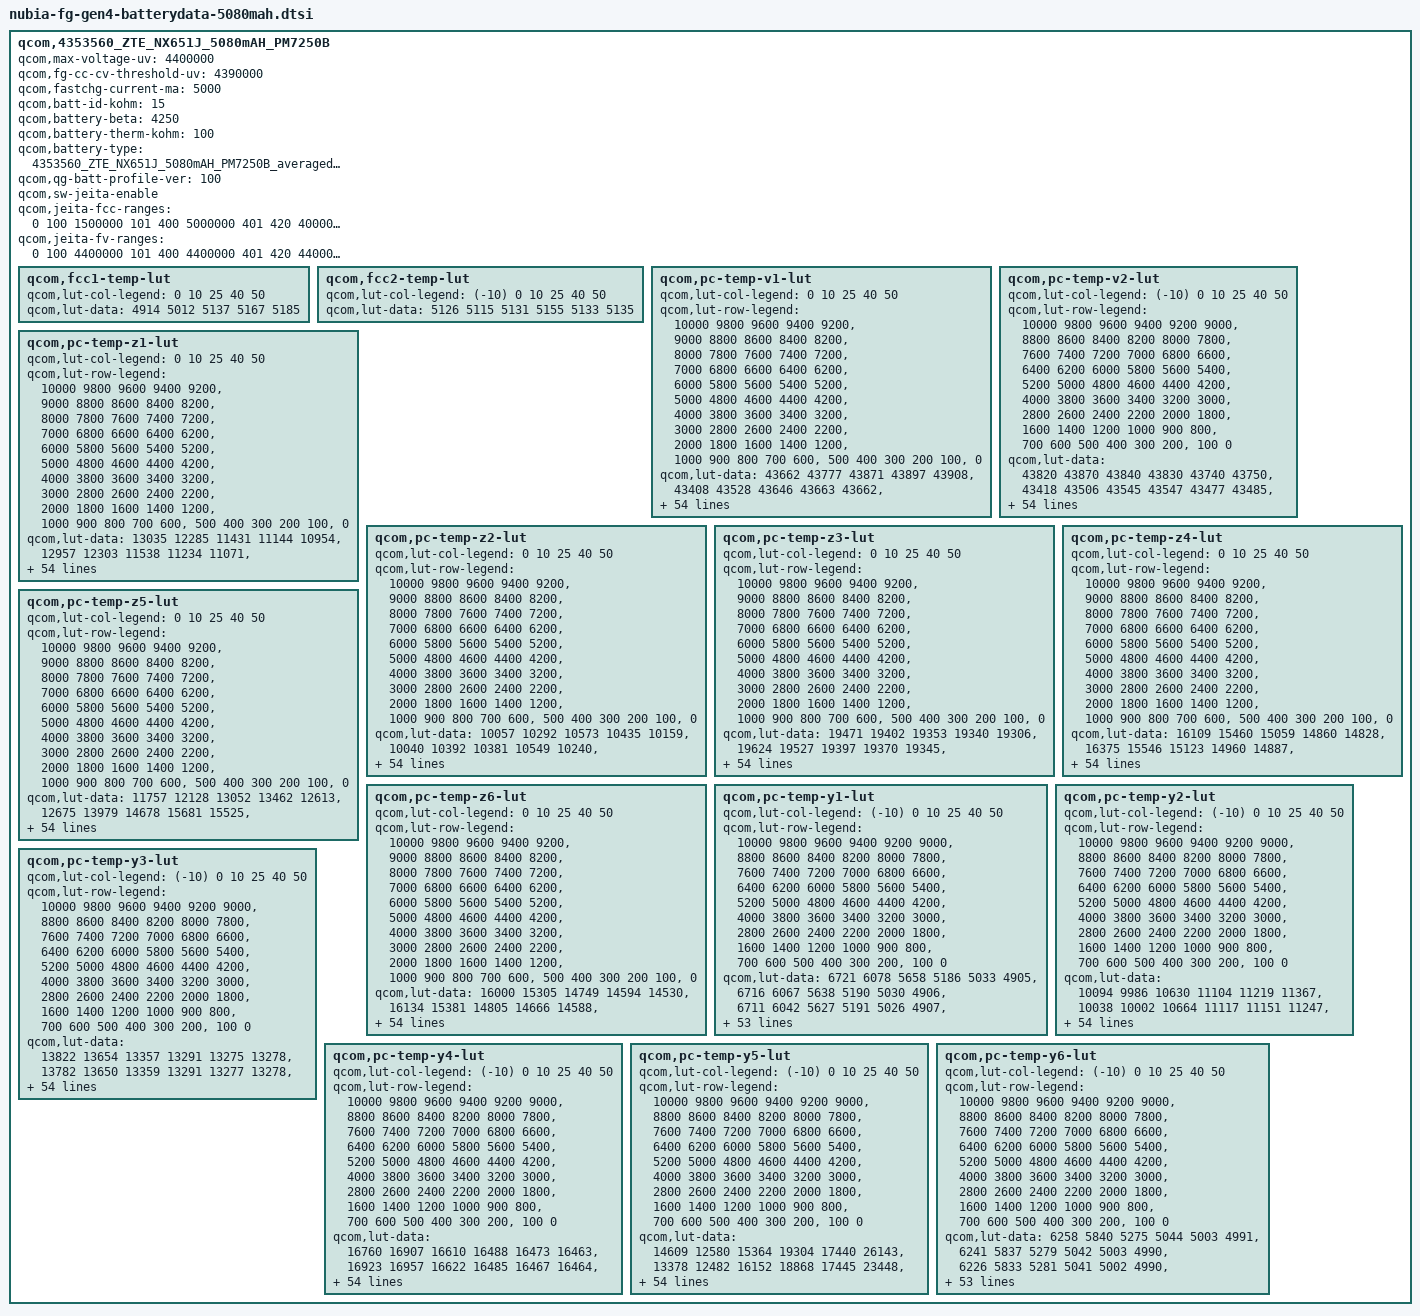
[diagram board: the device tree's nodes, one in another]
qcom,4353560_ZTE_NX651J_5080mAH_PM7250B {
    /* 4353560_ZTE_NX651J_5080mAH_PM7250B_averaged_MasterSlave_Dec16th2019 */
    qcom,max-voltage-uv = <4400000>;
    qcom,fg-cc-cv-threshold-uv = <4390000>;
    qcom,fastchg-current-ma = <5000>;
    qcom,batt-id-kohm = <15>;
    qcom,battery-beta = <4250>;
    qcom,battery-therm-kohm = <100>;
    qcom,battery-type = "4353560_ZTE_NX651J_5080mAH_PM7250B_averaged_MasterSlave_Dec16th2019";
    qcom,qg-batt-profile-ver = <100>;
	
	qcom,sw-jeita-enable;
	qcom,jeita-fcc-ranges = <0  100  1500000
							101 400  5000000
							401 420  4000000
							421 440  3500000
							441 520  1000000>;
	qcom,jeita-fv-ranges = <0   100  4400000
							101 400  4400000
							401 420  4400000
							421 440  4400000
							441 520  4100000>;
							
	qcom,fcc1-temp-lut {
		qcom,lut-col-legend = <0 10 25 40 50>;
		qcom,lut-data = <4914 5012 5137 5167 5185>;
	};

	qcom,fcc2-temp-lut {
		qcom,lut-col-legend = <(-10) 0 10 25 40 50>;
		qcom,lut-data = <5126 5115 5131 5155 5133 5135>;
	};

	qcom,pc-temp-v1-lut {
		qcom,lut-col-legend = <0 10 25 40 50>;
		qcom,lut-row-legend = <10000 9800 9600 9400 9200>,
			<9000 8800 8600 8400 8200>,
			<8000 7800 7600 7400 7200>,
			<7000 6800 6600 6400 6200>,
			<6000 5800 5600 5400 5200>,
			<5000 4800 4600 4400 4200>,
			<4000 3800 3600 3400 3200>,
			<3000 2800 2600 2400 2200>,
			<2000 1800 1600 1400 1200>,
			<1000 900 800 700 600>,
			<500 400 300 200 100>,
			<0>;
		qcom,lut-data = <43662 43777 43871 43897 43908>,
			<43408 43528 43646 43663 43662>,
			<43151 43282 43401 43429 43431>,
			<42897 43039 43155 43192 43200>,
			<42656 42799 42914 42959 42970>,
			<42425 42563 42674 42725 42740>,
			<42202 42332 42438 42491 42508>,
			<41988 42106 42205 42256 42274>,
			<41782 41885 41977 42024 42041>,
			<41580 41669 41751 41795 41812>,
			<41382 41466 41530 41570 41585>,
			<41185 41274 41321 41350 41364>,
			<40988 41078 41122 41133 41146>,
			<40790 40879 40918 40924 40936>,
			<40564 40671 40700 40720 40730>,
			<40273 40437 40483 40522 40529>,
			<40003 40169 40274 40329 40337>,
			<39838 39953 40071 40140 40154>,
			<39718 39818 39898 39963 39978>,
			<39603 39709 39763 39813 39822>,
			<39484 39586 39631 39662 39668>,
			<39369 39454 39470 39451 39465>,
			<39255 39312 39289 39163 39183>,
			<39144 39143 39087 38934 38952>,
			<39035 38960 38830 38788 38816>,
			<38930 38793 38612 38673 38710>,
			<38829 38627 38512 38577 38611>,
			<38729 38500 38447 38496 38522>,
			<38630 38425 38386 38420 38438>,
			<38537 38371 38324 38345 38359>,
			<38460 38326 38268 38276 38285>,
			<38390 38290 38219 38214 38214>,
			<38333 38258 38175 38158 38149>,
			<38287 38229 38132 38103 38084>,
			<38247 38203 38092 38051 38018>,
			<38210 38173 38053 37999 37953>,
			<38176 38141 38015 37951 37894>,
			<38137 38102 37977 37904 37839>,
			<38087 38044 37924 37842 37766>,
			<38022 37960 37845 37758 37659>,
			<37939 37862 37747 37659 37540>,
			<37815 37745 37636 37549 37433>,
			<37677 37608 37505 37423 37320>,
			<37528 37442 37347 37269 37164>,
			<37388 37297 37204 37129 37033>,
			<37283 37191 37103 37037 36953>,
			<37243 37163 37076 37002 36918>,
			<37214 37141 37053 36979 36897>,
			<37185 37124 37035 36961 36875>,
			<37142 37083 36995 36916 36818>,
			<36977 36891 36799 36692 36563>,
			<36550 36464 36376 36267 36126>,
			<35981 35899 35808 35695 35552>,
			<35209 35127 35030 34916 34771>,
			<33986 33913 33824 33708 33552>,
			<30000 30000 30000 30000 30000>;
	};

	qcom,pc-temp-v2-lut {
		qcom,lut-col-legend = <(-10) 0 10 25 40 50>;
		qcom,lut-row-legend = <10000 9800 9600 9400 9200 9000>,
			<8800 8600 8400 8200 8000 7800>,
			<7600 7400 7200 7000 6800 6600>,
			<6400 6200 6000 5800 5600 5400>,
			<5200 5000 4800 4600 4400 4200>,
			<4000 3800 3600 3400 3200 3000>,
			<2800 2600 2400 2200 2000 1800>,
			<1600 1400 1200 1000 900 800>,
			<700 600 500 400 300 200>,
			<100 0>;
		qcom,lut-data = <43820 43870 43840 43830 43740 43750>,
			<43418 43506 43545 43547 43477 43485>,
			<43057 43170 43264 43279 43222 43228>,
			<42742 42866 43000 43024 42977 42982>,
			<42463 42590 42752 42784 42741 42745>,
			<42213 42334 42508 42547 42507 42511>,
			<41998 42105 42263 42311 42274 42278>,
			<41796 41885 42023 42076 42041 42047>,
			<41560 41631 41790 41847 41813 41818>,
			<41288 41330 41565 41620 41587 41589>,
			<41061 41129 41349 41396 41364 41364>,
			<40925 41064 41151 41175 41143 41146>,
			<40797 41014 40958 40960 40925 40931>,
			<40529 40826 40758 40762 40719 40725>,
			<40030 40299 40552 40577 40521 40522>,
			<39637 39861 40327 40377 40327 40327>,
			<39437 39661 40051 40137 40130 40137>,
			<39280 39504 39771 39905 39939 39954>,
			<39119 39312 39559 39748 39769 39785>,
			<38964 39095 39389 39629 39618 39630>,
			<38814 38895 39218 39474 39444 39454>,
			<38664 38720 39029 39223 39212 39226>,
			<38526 38563 38848 38965 38974 38992>,
			<38412 38429 38693 38784 38792 38808>,
			<38315 38309 38556 38636 38639 38651>,
			<38230 38214 38435 38510 38510 38517>,
			<38153 38144 38329 38402 38401 38405>,
			<38084 38087 38232 38305 38305 38305>,
			<38020 38034 38139 38213 38217 38213>,
			<37960 37987 38048 38126 38137 38127>,
			<37900 37942 37974 38051 38064 38052>,
			<37836 37897 37915 37982 37996 37986>,
			<37774 37852 37864 37921 37930 37924>,
			<37713 37805 37818 37864 37864 37855>,
			<37656 37756 37777 37812 37797 37781>,
			<37599 37704 37735 37757 37725 37697>,
			<37540 37651 37693 37698 37644 37594>,
			<37483 37595 37646 37636 37561 37488>,
			<37428 37533 37580 37570 37483 37400>,
			<37378 37465 37496 37499 37406 37321>,
			<37324 37386 37407 37420 37323 37238>,
			<37266 37283 37316 37329 37231 37153>,
			<37203 37174 37208 37215 37123 37048>,
			<37134 37070 37067 37078 36986 36905>,
			<37067 36975 36949 36965 36888 36811>,
			<36957 36881 36860 36900 36841 36766>,
			<36889 36839 36814 36883 36828 36754>,
			<36816 36782 36765 36863 36810 36737>,
			<36726 36717 36700 36836 36778 36704>,
			<36569 36604 36564 36766 36660 36577>,
			<36322 36404 36277 36535 36317 36234>,
			<35962 35992 35789 36058 35787 35714>,
			<35402 35358 35113 35424 35097 35032>,
			<34568 34432 34139 34561 34081 34041>,
			<33168 32950 32613 33262 32819 32820>,
			<28487 28690 28568 28393 28320 28176>;
	};

	qcom,pc-temp-z1-lut {
		qcom,lut-col-legend = <0 10 25 40 50>;
		qcom,lut-row-legend = <10000 9800 9600 9400 9200>,
			<9000 8800 8600 8400 8200>,
			<8000 7800 7600 7400 7200>,
			<7000 6800 6600 6400 6200>,
			<6000 5800 5600 5400 5200>,
			<5000 4800 4600 4400 4200>,
			<4000 3800 3600 3400 3200>,
			<3000 2800 2600 2400 2200>,
			<2000 1800 1600 1400 1200>,
			<1000 900 800 700 600>,
			<500 400 300 200 100>,
			<0>;
		qcom,lut-data = <13035 12285 11431 11144 10954>,
			<12957 12303 11538 11234 11071>,
			<12976 12308 11531 11239 11071>,
			<12997 12306 11523 11240 11071>,
			<12992 12301 11515 11236 11071>,
			<12965 12288 11507 11226 11070>,
			<12951 12262 11496 11217 11070>,
			<12973 12243 11482 11211 11066>,
			<13004 12233 11470 11205 11063>,
			<13006 12225 11462 11201 11061>,
			<12977 12216 11455 11198 11060>,
			<12942 12206 11451 11198 11060>,
			<12914 12194 11447 11201 11060>,
			<12887 12167 11442 11203 11060>,
			<12860 12137 11429 11201 11062>,
			<12830 12119 11417 11198 11066>,
			<12806 12106 11416 11196 11068>,
			<12800 12099 11417 11195 11070>,
			<12797 12096 11419 11194 11072>,
			<12793 12094 11426 11198 11074>,
			<12785 12095 11433 11204 11077>,
			<12776 12103 11438 11206 11078>,
			<12770 12113 11442 11207 11078>,
			<12764 12124 11446 11208 11079>,
			<12761 12134 11452 11209 11081>,
			<12772 12136 11456 11211 11084>,
			<12793 12132 11458 11213 11086>,
			<12798 12130 11460 11217 11089>,
			<12775 12134 11462 11221 11092>,
			<12751 12145 11467 11226 11095>,
			<12743 12157 11474 11231 11098>,
			<12739 12171 11481 11236 11102>,
			<12738 12181 11490 11241 11107>,
			<12750 12179 11495 11247 11111>,
			<12768 12175 11498 11253 11117>,
			<12778 12174 11501 11259 11122>,
			<12784 12183 11508 11264 11125>,
			<12791 12197 11517 11269 11127>,
			<12806 12210 11526 11273 11130>,
			<12828 12225 11536 11278 11135>,
			<12842 12237 11545 11284 11141>,
			<12850 12245 11551 11290 11144>,
			<12861 12257 11556 11296 11147>,
			<12879 12293 11567 11304 11153>,
			<12885 12314 11583 11310 11158>,
			<12894 12299 11589 11314 11160>,
			<12885 12310 11586 11319 11160>,
			<12889 12281 11582 11316 11162>,
			<12925 12272 11580 11322 11164>,
			<12893 12295 11598 11321 11168>,
			<12909 12293 11598 11332 11174>,
			<12931 12315 11607 11343 11179>,
			<12910 12328 11624 11351 11190>,
			<12961 12408 11650 11370 11204>,
			<12961 12408 11650 11370 11204>,
			<12961 12408 11650 11370 11204>;
	};

	qcom,pc-temp-z2-lut {
		qcom,lut-col-legend = <0 10 25 40 50>;
		qcom,lut-row-legend = <10000 9800 9600 9400 9200>,
			<9000 8800 8600 8400 8200>,
			<8000 7800 7600 7400 7200>,
			<7000 6800 6600 6400 6200>,
			<6000 5800 5600 5400 5200>,
			<5000 4800 4600 4400 4200>,
			<4000 3800 3600 3400 3200>,
			<3000 2800 2600 2400 2200>,
			<2000 1800 1600 1400 1200>,
			<1000 900 800 700 600>,
			<500 400 300 200 100>,
			<0>;
		qcom,lut-data = <10057 10292 10573 10435 10159>,
			<10040 10392 10381 10549 10240>,
			<10138 10418 10492 10554 10363>,
			<10268 10390 10550 10556 10461>,
			<10346 10354 10526 10540 10471>,
			<10408 10327 10484 10501 10471>,
			<10433 10302 10445 10471 10471>,
			<10432 10289 10404 10451 10447>,
			<10429 10282 10373 10429 10413>,
			<10424 10278 10351 10393 10383>,
			<10407 10274 10336 10353 10353>,
			<10384 10270 10336 10346 10346>,
			<10358 10268 10342 10357 10367>,
			<10325 10267 10352 10370 10385>,
			<10291 10267 10390 10380 10381>,
			<10250 10267 10426 10388 10370>,
			<10221 10268 10424 10381 10370>,
			<10219 10269 10408 10339 10391>,
			<10221 10294 10404 10314 10406>,
			<10224 10337 10438 10321 10386>,
			<10226 10363 10487 10339 10351>,
			<10229 10380 10529 10406 10392>,
			<10230 10399 10572 10596 10672>,
			<10232 10441 10581 10690 10852>,
			<10234 10488 10529 10550 10659>,
			<10239 10503 10479 10365 10373>,
			<10248 10507 10488 10321 10335>,
			<10260 10509 10523 10304 10368>,
			<10279 10510 10557 10299 10385>,
			<10300 10511 10591 10315 10386>,
			<10317 10512 10618 10346 10386>,
			<10332 10516 10628 10399 10393>,
			<10345 10519 10634 10483 10418>,
			<10357 10518 10643 10542 10428>,
			<10368 10515 10658 10582 10384>,
			<10382 10515 10668 10604 10337>,
			<10399 10518 10662 10590 10340>,
			<10420 10524 10652 10554 10364>,
			<10460 10539 10654 10549 10392>,
			<10508 10569 10695 10618 10427>,
			<10526 10584 10727 10678 10464>,
			<10530 10586 10724 10651 10502>,
			<10548 10589 10719 10610 10533>,
			<10653 10615 10728 10642 10546>,
			<10582 10796 10798 10649 10537>,
			<10389 10908 10865 10605 10486>,
			<10424 10901 10758 10562 10428>,
			<10358 10949 10768 10570 10465>,
			<10227 11016 10918 10624 10495>,
			<10189 11123 10895 10691 10724>,
			<10190 11067 10873 10608 10558>,
			<10208 11015 10881 10468 10229>,
			<10108 10863 10759 10307 10159>,
			<9916 10565 10662 10327 10096>,
			<9916 10565 10662 10327 10096>,
			<9916 10565 10662 10327 10096>;
	};

	qcom,pc-temp-z3-lut {
		qcom,lut-col-legend = <0 10 25 40 50>;
		qcom,lut-row-legend = <10000 9800 9600 9400 9200>,
			<9000 8800 8600 8400 8200>,
			<8000 7800 7600 7400 7200>,
			<7000 6800 6600 6400 6200>,
			<6000 5800 5600 5400 5200>,
			<5000 4800 4600 4400 4200>,
			<4000 3800 3600 3400 3200>,
			<3000 2800 2600 2400 2200>,
			<2000 1800 1600 1400 1200>,
			<1000 900 800 700 600>,
			<500 400 300 200 100>,
			<0>;
		qcom,lut-data = <19471 19402 19353 19340 19306>,
			<19624 19527 19397 19370 19345>,
			<19723 19590 19437 19398 19366>,
			<19782 19619 19460 19414 19387>,
			<19779 19633 19473 19421 19398>,
			<19749 19634 19480 19424 19406>,
			<19719 19632 19480 19427 19410>,
			<19690 19632 19476 19429 19413>,
			<19666 19634 19472 19430 19415>,
			<19661 19636 19470 19429 19414>,
			<19662 19632 19467 19426 19411>,
			<19663 19615 19463 19422 19407>,
			<19668 19597 19459 19417 19400>,
			<19680 19576 19453 19411 19392>,
			<19695 19558 19444 19404 19387>,
			<19722 19557 19435 19395 19383>,
			<19743 19562 19429 19389 19378>,
			<19731 19565 19424 19384 19373>,
			<19689 19540 19419 19379 19367>,
			<19667 19503 19409 19371 19359>,
			<19667 19497 19401 19364 19352>,
			<19668 19503 19403 19366 19352>,
			<19668 19511 19412 19378 19358>,
			<19668 19524 19416 19384 19362>,
			<19668 19538 19417 19376 19351>,
			<19668 19541 19417 19363 19335>,
			<19670 19541 19415 19358 19328>,
			<19672 19540 19410 19355 19325>,
			<19675 19540 19407 19354 19324>,
			<19678 19539 19407 19355 19325>,
			<19676 19537 19407 19356 19327>,
			<19669 19532 19406 19358 19330>,
			<19661 19526 19405 19359 19336>,
			<19651 19521 19405 19362 19342>,
			<19640 19515 19407 19369 19349>,
			<19624 19510 19410 19375 19355>,
			<19603 19502 19407 19374 19352>,
			<19585 19497 19401 19369 19344>,
			<19572 19497 19398 19366 19342>,
			<19562 19497 19398 19365 19344>,
			<19561 19497 19397 19363 19346>,
			<19570 19490 19393 19360 19347>,
			<19573 19482 19387 19356 19349>,
			<19540 19478 19387 19358 19355>,
			<19389 19442 19378 19356 19354>,
			<19326 19428 19367 19338 19334>,
			<19322 19410 19356 19338 19333>,
			<19312 19381 19356 19341 19323>,
			<19307 19323 19331 19331 19319>,
			<19306 19317 19332 19322 19304>,
			<19306 19382 19346 19338 19328>,
			<19325 19382 19339 19355 19356>,
			<19335 19364 19336 19358 19356>,
			<19341 19335 19343 19356 19346>,
			<19341 19335 19343 19356 19346>,
			<19341 19335 19343 19356 19346>;
	};

	qcom,pc-temp-z4-lut {
		qcom,lut-col-legend = <0 10 25 40 50>;
		qcom,lut-row-legend = <10000 9800 9600 9400 9200>,
			<9000 8800 8600 8400 8200>,
			<8000 7800 7600 7400 7200>,
			<7000 6800 6600 6400 6200>,
			<6000 5800 5600 5400 5200>,
			<5000 4800 4600 4400 4200>,
			<4000 3800 3600 3400 3200>,
			<3000 2800 2600 2400 2200>,
			<2000 1800 1600 1400 1200>,
			<1000 900 800 700 600>,
			<500 400 300 200 100>,
			<0>;
		qcom,lut-data = <16109 15460 15059 14860 14828>,
			<16375 15546 15123 14960 14887>,
			<16260 15550 15080 14938 14879>,
			<16087 15419 15028 14906 14863>,
			<15939 15249 14967 14874 14842>,
			<15789 15143 14906 14837 14811>,
			<15657 15055 14865 14807 14785>,
			<15550 14983 14834 14781 14764>,
			<15458 14922 14807 14758 14745>,
			<15376 14874 14782 14740 14728>,
			<15306 14844 14760 14724 14712>,
			<15238 14823 14741 14712 14702>,
			<15165 14804 14723 14701 14697>,
			<15093 14787 14712 14693 14693>,
			<15037 14772 14704 14687 14689>,
			<14990 14755 14699 14683 14685>,
			<14954 14736 14695 14680 14681>,
			<14933 14728 14692 14676 14677>,
			<14918 14728 14688 14672 14673>,
			<14901 14729 14676 14665 14668>,
			<14875 14726 14666 14657 14662>,
			<14845 14705 14667 14670 14671>,
			<14823 14691 14675 14726 14728>,
			<14805 14695 14690 14768 14776>,
			<14789 14705 14750 14788 14792>,
			<14774 14720 14804 14800 14803>,
			<14760 14752 14803 14798 14802>,
			<14748 14774 14790 14789 14794>,
			<14738 14770 14777 14778 14784>,
			<14731 14760 14765 14766 14772>,
			<14730 14750 14752 14752 14759>,
			<14730 14738 14739 14738 14742>,
			<14730 14725 14726 14724 14723>,
			<14729 14716 14713 14708 14705>,
			<14728 14707 14700 14691 14687>,
			<14730 14700 14688 14677 14674>,
			<14740 14693 14679 14669 14667>,
			<14746 14687 14671 14663 14663>,
			<14745 14683 14670 14662 14663>,
			<14740 14680 14671 14667 14674>,
			<14733 14680 14674 14673 14685>,
			<14714 14685 14680 14679 14682>,
			<14708 14688 14684 14683 14675>,
			<14719 14684 14683 14682 14674>,
			<14801 14677 14674 14674 14668>,
			<14851 14667 14663 14669 14661>,
			<14852 14677 14666 14665 14659>,
			<14857 14703 14655 14649 14655>,
			<14860 14763 14668 14641 14638>,
			<14856 14765 14659 14639 14638>,
			<14852 14695 14661 14648 14649>,
			<14853 14714 14692 14655 14649>,
			<14864 14746 14705 14661 14656>,
			<14878 14792 14703 14669 14672>,
			<14878 14792 14703 14669 14672>,
			<14878 14792 14703 14669 14672>;
	};

	qcom,pc-temp-z5-lut {
		qcom,lut-col-legend = <0 10 25 40 50>;
		qcom,lut-row-legend = <10000 9800 9600 9400 9200>,
			<9000 8800 8600 8400 8200>,
			<8000 7800 7600 7400 7200>,
			<7000 6800 6600 6400 6200>,
			<6000 5800 5600 5400 5200>,
			<5000 4800 4600 4400 4200>,
			<4000 3800 3600 3400 3200>,
			<3000 2800 2600 2400 2200>,
			<2000 1800 1600 1400 1200>,
			<1000 900 800 700 600>,
			<500 400 300 200 100>,
			<0>;
		qcom,lut-data = <11757 12128 13052 13462 12613>,
			<12675 13979 14678 15681 15525>,
			<13441 15147 16033 17487 17476>,
			<13992 15824 17087 18788 19534>,
			<14208 16357 17920 19353 20719>,
			<14331 16857 18557 19718 21528>,
			<14412 17300 18920 20311 22520>,
			<14460 17946 19139 21347 23914>,
			<14500 19387 19457 22433 25474>,
			<14584 20730 20098 23263 27250>,
			<14764 21038 20977 24051 29128>,
			<15009 21170 22050 25159 29819>,
			<15302 21204 23408 26896 29913>,
			<15707 20813 24547 27876 30019>,
			<16361 20313 25554 27791 30669>,
			<18017 21424 26231 27652 32018>,
			<19451 26375 26327 27710 33294>,
			<19139 29328 26349 28225 34717>,
			<17816 26065 26418 28913 35511>,
			<17148 21222 26955 29575 35464>,
			<17623 20793 28079 30594 35372>,
			<18544 24429 34136 36151 36513>,
			<19501 30253 47221 53177 43189>,
			<20627 45454 51938 61687 47484>,
			<22062 65396 51397 49619 38993>,
			<24020 65535 50304 33120 25621>,
			<26673 65535 46644 27518 21323>,
			<30240 65535 39515 24578 19617>,
			<36637 62693 35433 23374 18802>,
			<41793 58279 33530 22957 18410>,
			<42575 54394 32341 22754 18198>,
			<42874 51104 31651 22873 18438>,
			<42914 47919 31177 23433 19608>,
			<40636 44442 31341 24493 21351>,
			<36576 40901 33920 28601 25664>,
			<32360 38342 36068 33042 29580>,
			<27062 36311 36067 35035 29955>,
			<23682 35068 35971 36397 30003>,
			<22850 36337 36133 36976 30393>,
			<22356 40442 37638 37247 34440>,
			<22922 42189 38809 37371 38138>,
			<28310 37096 34652 32941 34651>,
			<30273 33675 29336 26346 28760>,
			<25564 35357 29853 27052 32796>,
			<16110 32000 29562 27199 33421>,
			<13241 31525 27826 21674 22861>,
			<13061 24093 23061 21640 21745>,
			<12724 18300 23468 23741 19287>,
			<12560 13580 17503 21824 20777>,
			<12532 13508 18290 20198 17877>,
			<12712 19035 20933 23755 24596>,
			<13129 17710 16430 21048 24987>,
			<13040 15333 15253 20347 22117>,
			<12814 13380 15377 17786 16735>,
			<12814 13380 15377 17786 16735>,
			<12814 13380 15377 17786 16735>;
	};

	qcom,pc-temp-z6-lut {
		qcom,lut-col-legend = <0 10 25 40 50>;
		qcom,lut-row-legend = <10000 9800 9600 9400 9200>,
			<9000 8800 8600 8400 8200>,
			<8000 7800 7600 7400 7200>,
			<7000 6800 6600 6400 6200>,
			<6000 5800 5600 5400 5200>,
			<5000 4800 4600 4400 4200>,
			<4000 3800 3600 3400 3200>,
			<3000 2800 2600 2400 2200>,
			<2000 1800 1600 1400 1200>,
			<1000 900 800 700 600>,
			<500 400 300 200 100>,
			<0>;
		qcom,lut-data = <16000 15305 14749 14594 14530>,
			<16134 15381 14805 14666 14588>,
			<16090 15393 14804 14666 14600>,
			<16017 15329 14804 14667 14607>,
			<15933 15243 14783 14660 14605>,
			<15821 15181 14751 14643 14595>,
			<15721 15125 14730 14629 14586>,
			<15640 15080 14713 14619 14579>,
			<15570 15045 14699 14609 14572>,
			<15516 15015 14686 14600 14565>,
			<15474 14989 14674 14591 14557>,
			<15435 14966 14663 14583 14550>,
			<15392 14942 14653 14576 14544>,
			<15350 14914 14643 14570 14538>,
			<15319 14887 14632 14562 14533>,
			<15299 14872 14622 14555 14528>,
			<15280 14862 14616 14550 14524>,
			<15255 14852 14612 14545 14520>,
			<15226 14837 14607 14541 14515>,
			<15205 14824 14598 14533 14508>,
			<15190 14820 14591 14526 14501>,
			<15179 14818 14593 14533 14505>,
			<15169 14818 14600 14566 14536>,
			<15160 14824 14611 14584 14556>,
			<15153 14838 14638 14586 14555>,
			<15145 14851 14661 14587 14553>,
			<15139 14866 14659 14586 14550>,
			<15134 14874 14652 14580 14545>,
			<15131 14874 14646 14575 14541>,
			<15128 14870 14642 14571 14537>,
			<15127 14866 14638 14567 14533>,
			<15126 14860 14633 14563 14528>,
			<15124 14853 14628 14558 14524>,
			<15120 14847 14624 14554 14520>,
			<15116 14843 14621 14552 14517>,
			<15112 14839 14617 14549 14515>,
			<15108 14836 14613 14546 14511>,
			<15106 14834 14608 14542 14506>,
			<15107 14835 14607 14541 14504>,
			<15108 14839 14610 14542 14511>,
			<15111 14843 14612 14544 14516>,
			<15119 14847 14613 14545 14516>,
			<15122 14850 14614 14546 14514>,
			<15122 14854 14615 14548 14517>,
			<15099 14843 14611 14545 14515>,
			<15090 14834 14601 14534 14502>,
			<15087 14830 14598 14532 14501>,
			<15085 14827 14593 14527 14495>,
			<15085 14823 14586 14519 14485>,
			<15087 14825 14584 14513 14477>,
			<15094 14834 14594 14527 14495>,
			<15111 14848 14607 14542 14513>,
			<15133 14862 14615 14549 14520>,
			<15161 14880 14623 14556 14525>,
			<15161 14880 14623 14556 14525>,
			<15161 14880 14623 14556 14525>;
	};

	qcom,pc-temp-y1-lut {
		qcom,lut-col-legend = <(-10) 0 10 25 40 50>;
		qcom,lut-row-legend = <10000 9800 9600 9400 9200 9000>,
			<8800 8600 8400 8200 8000 7800>,
			<7600 7400 7200 7000 6800 6600>,
			<6400 6200 6000 5800 5600 5400>,
			<5200 5000 4800 4600 4400 4200>,
			<4000 3800 3600 3400 3200 3000>,
			<2800 2600 2400 2200 2000 1800>,
			<1600 1400 1200 1000 900 800>,
			<700 600 500 400 300 200>,
			<100 0>;
		qcom,lut-data = <6721 6078 5658 5186 5033 4905>,
			<6716 6067 5638 5190 5030 4906>,
			<6711 6042 5627 5191 5026 4907>,
			<6706 6014 5621 5190 5022 4907>,
			<6702 5990 5619 5188 5017 4906>,
			<6698 5980 5618 5185 5012 4906>,
			<6695 5979 5624 5180 5005 4904>,
			<6692 5979 5632 5174 4998 4902>,
			<6689 5979 5629 5167 4996 4901>,
			<6687 5976 5614 5158 4995 4901>,
			<6685 5975 5605 5153 4994 4901>,
			<6682 5990 5608 5151 4993 4901>,
			<6679 6012 5613 5150 4992 4899>,
			<6681 6020 5612 5148 4989 4898>,
			<6690 6023 5605 5146 4986 4897>,
			<6695 6026 5601 5145 4984 4897>,
			<6692 6028 5610 5149 4986 4898>,
			<6688 6029 5621 5153 4989 4899>,
			<6687 6029 5619 5153 4989 4900>,
			<6688 6027 5608 5152 4987 4901>,
			<6688 6025 5602 5151 4986 4902>,
			<6688 6008 5605 5150 4987 4902>,
			<6686 5987 5609 5149 4989 4901>,
			<6683 5989 5609 5153 4991 4902>,
			<6674 6013 5609 5162 4992 4904>,
			<6670 6027 5608 5165 4994 4906>,
			<6670 6027 5612 5162 4997 4908>,
			<6670 6026 5619 5159 5001 4910>,
			<6667 6026 5626 5166 5004 4912>,
			<6659 6023 5634 5181 5007 4915>,
			<6655 6021 5637 5186 5010 4917>,
			<6657 6019 5633 5186 5013 4919>,
			<6660 6018 5628 5186 5016 4922>,
			<6660 6018 5633 5194 5018 4926>,
			<6657 6018 5650 5208 5021 4931>,
			<6654 6018 5656 5212 5023 4935>,
			<6651 6030 5649 5209 5025 4936>,
			<6648 6045 5641 5207 5028 4938>,
			<6645 6040 5641 5208 5030 4939>,
			<6642 6017 5641 5211 5031 4940>,
			<6640 6006 5642 5215 5033 4941>,
			<6638 6007 5642 5221 5034 4944>,
			<6637 6006 5644 5222 5036 4948>,
			<6640 5987 5666 5218 5043 4952>,
			<6642 5981 5670 5236 5049 4951>,
			<6670 6009 5670 5242 5050 4952>,
			<6664 6029 5668 5245 5052 4953>,
			<6675 6030 5662 5245 5059 4952>,
			<6683 6027 5662 5253 5058 4955>,
			<6690 6025 5665 5253 5055 4954>,
			<6721 6063 5669 5253 5057 4955>,
			<6776 6023 5677 5259 5065 4959>,
			<6824 6093 5680 5280 5076 4972>,
			<6897 6187 5704 5309 5088 4983>,
			<6897 6187 5704 5309 5088 4983>,
			<6897 6187 5704 5309 5088 4983>;
	};

	qcom,pc-temp-y2-lut {
		qcom,lut-col-legend = <(-10) 0 10 25 40 50>;
		qcom,lut-row-legend = <10000 9800 9600 9400 9200 9000>,
			<8800 8600 8400 8200 8000 7800>,
			<7600 7400 7200 7000 6800 6600>,
			<6400 6200 6000 5800 5600 5400>,
			<5200 5000 4800 4600 4400 4200>,
			<4000 3800 3600 3400 3200 3000>,
			<2800 2600 2400 2200 2000 1800>,
			<1600 1400 1200 1000 900 800>,
			<700 600 500 400 300 200>,
			<100 0>;
		qcom,lut-data = <10094 9986 10630 11104 11219 11367>,
			<10038 10002 10664 11117 11151 11247>,
			<10022 10025 10698 11119 11081 11121>,
			<10037 10053 10728 11112 11020 11009>,
			<10075 10086 10748 11099 10976 10928>,
			<10126 10124 10755 11082 10961 10899>,
			<10214 10163 10748 11053 10973 10925>,
			<10314 10209 10737 11023 10993 10961>,
			<10367 10286 10738 11007 11007 10956>,
			<10396 10419 10755 10997 11017 10902>,
			<10429 10490 10778 10994 11022 10856>,
			<10487 10484 10801 11020 11021 10831>,
			<10540 10477 10833 11061 11019 10814>,
			<10435 10496 10897 11084 11022 10826>,
			<9957 10609 11016 11098 11038 10891>,
			<9687 10752 11074 11123 11058 10955>,
			<9681 10958 11060 11197 11079 10999>,
			<9678 11152 11041 11293 11109 11044>,
			<9675 11000 11041 11373 11186 11111>,
			<9672 10211 11056 11448 11345 11204>,
			<9670 9738 11077 11470 11418 11242>,
			<9670 9714 11116 11411 11364 11193>,
			<9670 9701 11162 11349 11282 11134>,
			<9670 9694 11193 11352 11222 11140>,
			<9669 9688 11217 11374 11167 11179>,
			<9668 9684 11244 11391 11148 11197>,
			<9667 9681 11292 11404 11171 11197>,
			<9666 9679 11331 11412 11215 11197>,
			<9666 9676 11322 11408 11282 11242>,
			<9665 9674 11278 11398 11386 11382>,
			<9665 9671 11240 11401 11454 11462>,
			<9664 9670 11215 11472 11491 11483>,
			<9664 9668 11190 11550 11512 11498>,
			<9664 9667 11157 11584 11488 11519>,
			<9663 9666 11116 11608 11419 11540>,
			<9663 9664 11067 11607 11391 11539>,
			<9662 9663 11015 11559 11405 11405>,
			<9662 9662 10936 11510 11419 11271>,
			<9661 9661 10631 11492 11404 11279>,
			<9661 9660 10026 11478 11362 11317>,
			<9660 9659 9833 11459 11352 11330>,
			<9660 9659 10287 11430 11418 11322>,
			<9659 9659 10455 11391 11425 11288>,
			<9658 9658 9869 11327 11166 11103>,
			<9657 9658 9746 11166 11062 10934>,
			<9657 9657 9737 11260 11084 10837>,
			<9656 9657 9714 11162 11100 10809>,
			<9656 9657 9698 11196 11044 10901>,
			<9655 9656 9692 11224 11074 10911>,
			<9653 9656 9686 11178 11147 10903>,
			<9652 9655 9675 11136 11023 10839>,
			<9650 9654 9666 11049 10980 10716>,
			<9649 9653 9661 10941 10898 10670>,
			<9649 9651 9657 10754 10789 10521>,
			<9649 9651 9657 10754 10789 10521>,
			<9649 9651 9657 10754 10789 10521>;
	};

	qcom,pc-temp-y3-lut {
		qcom,lut-col-legend = <(-10) 0 10 25 40 50>;
		qcom,lut-row-legend = <10000 9800 9600 9400 9200 9000>,
			<8800 8600 8400 8200 8000 7800>,
			<7600 7400 7200 7000 6800 6600>,
			<6400 6200 6000 5800 5600 5400>,
			<5200 5000 4800 4600 4400 4200>,
			<4000 3800 3600 3400 3200 3000>,
			<2800 2600 2400 2200 2000 1800>,
			<1600 1400 1200 1000 900 800>,
			<700 600 500 400 300 200>,
			<100 0>;
		qcom,lut-data = <13822 13654 13357 13291 13275 13278>,
			<13782 13650 13359 13291 13277 13278>,
			<13747 13645 13362 13292 13279 13278>,
			<13718 13639 13365 13292 13280 13278>,
			<13699 13634 13367 13293 13282 13278>,
			<13693 13632 13369 13294 13283 13278>,
			<13702 13631 13370 13295 13284 13279>,
			<13716 13631 13370 13295 13285 13282>,
			<13694 13613 13370 13296 13286 13282>,
			<13587 13531 13370 13297 13287 13282>,
			<13523 13481 13370 13298 13288 13282>,
			<13530 13483 13370 13300 13288 13284>,
			<13540 13486 13370 13303 13288 13287>,
			<13537 13486 13368 13305 13289 13288>,
			<13519 13481 13361 13306 13293 13289>,
			<13506 13472 13354 13306 13295 13290>,
			<13504 13452 13352 13303 13295 13289>,
			<13502 13425 13350 13299 13293 13289>,
			<13502 13408 13347 13300 13293 13289>,
			<13504 13394 13343 13303 13293 13291>,
			<13508 13388 13339 13304 13293 13292>,
			<13517 13386 13335 13301 13290 13286>,
			<13530 13385 13331 13295 13286 13280>,
			<13539 13383 13327 13291 13283 13278>,
			<13546 13379 13323 13288 13280 13277>,
			<13555 13377 13321 13287 13279 13277>,
			<13571 13384 13319 13287 13279 13277>,
			<13591 13398 13318 13287 13279 13277>,
			<13614 13413 13317 13287 13280 13277>,
			<13640 13432 13315 13285 13281 13275>,
			<13664 13454 13315 13285 13281 13275>,
			<13685 13477 13315 13287 13282 13276>,
			<13706 13502 13315 13289 13283 13277>,
			<13733 13530 13315 13290 13283 13279>,
			<13765 13561 13316 13291 13282 13280>,
			<13799 13598 13317 13291 13282 13280>,
			<13836 13641 13320 13291 13282 13279>,
			<13875 13689 13323 13290 13281 13279>,
			<13918 13737 13324 13290 13282 13279>,
			<13965 13785 13323 13291 13283 13280>,
			<14014 13835 13324 13291 13284 13282>,
			<14065 13885 13334 13291 13284 13283>,
			<14126 13937 13346 13291 13284 13283>,
			<14210 13994 13358 13289 13279 13279>,
			<14306 14052 13383 13289 13282 13282>,
			<14295 14045 13392 13292 13288 13286>,
			<14398 14116 13411 13296 13292 13288>,
			<14542 14170 13441 13302 13295 13291>,
			<14725 14241 13473 13308 13298 13292>,
			<15046 14314 13505 13311 13298 13289>,
			<15652 14405 13551 13309 13293 13288>,
			<16558 14531 13625 13308 13292 13288>,
			<17963 14925 13782 13313 13298 13292>,
			<20454 15819 14162 13326 13306 13300>,
			<20454 15819 14162 13326 13306 13300>,
			<20454 15819 14162 13326 13306 13300>;
	};

	qcom,pc-temp-y4-lut {
		qcom,lut-col-legend = <(-10) 0 10 25 40 50>;
		qcom,lut-row-legend = <10000 9800 9600 9400 9200 9000>,
			<8800 8600 8400 8200 8000 7800>,
			<7600 7400 7200 7000 6800 6600>,
			<6400 6200 6000 5800 5600 5400>,
			<5200 5000 4800 4600 4400 4200>,
			<4000 3800 3600 3400 3200 3000>,
			<2800 2600 2400 2200 2000 1800>,
			<1600 1400 1200 1000 900 800>,
			<700 600 500 400 300 200>,
			<100 0>;
		qcom,lut-data = <16760 16907 16610 16488 16473 16463>,
			<16923 16957 16622 16485 16467 16464>,
			<17033 16995 16639 16484 16464 16464>,
			<17099 17023 16657 16484 16462 16464>,
			<17130 17040 16671 16485 16462 16463>,
			<17139 17045 16676 16486 16462 16463>,
			<17094 17033 16674 16488 16463 16462>,
			<17029 17015 16672 16492 16466 16461>,
			<17055 17027 16673 16497 16469 16461>,
			<17220 17117 16681 16502 16472 16466>,
			<17318 17224 16693 16508 16477 16469>,
			<17316 17350 16713 16513 16483 16470>,
			<17311 17461 16742 16518 16490 16470>,
			<17265 17400 16783 16530 16496 16472>,
			<17087 17039 16843 16553 16501 16477>,
			<16976 16825 16870 16574 16508 16483>,
			<16960 16832 16800 16592 16519 16491>,
			<16950 16841 16702 16609 16535 16500>,
			<16933 16840 16671 16629 16555 16514>,
			<16911 16825 16659 16653 16584 16535>,
			<16883 16802 16643 16657 16596 16544>,
			<16837 16757 16608 16586 16556 16527>,
			<16795 16705 16571 16505 16501 16500>,
			<16786 16677 16557 16484 16479 16481>,
			<16783 16659 16550 16474 16465 16464>,
			<16781 16652 16546 16471 16461 16458>,
			<16779 16653 16543 16474 16463 16459>,
			<16778 16655 16541 16478 16468 16462>,
			<16775 16658 16535 16483 16474 16467>,
			<16769 16661 16524 16491 16481 16476>,
			<16766 16665 16520 16497 16489 16486>,
			<16771 16671 16522 16502 16499 16498>,
			<16778 16679 16526 16507 16505 16507>,
			<16782 16686 16533 16512 16506 16507>,
			<16785 16694 16546 16515 16506 16507>,
			<16789 16701 16559 16516 16505 16505>,
			<16796 16705 16570 16510 16493 16487>,
			<16806 16710 16583 16505 16479 16469>,
			<16817 16723 16606 16502 16477 16469>,
			<16831 16747 16636 16499 16477 16472>,
			<16849 16758 16644 16500 16477 16476>,
			<16873 16732 16616 16507 16484 16487>,
			<16901 16713 16603 16505 16486 16488>,
			<16933 16713 16619 16494 16473 16460>,
			<16925 16719 16640 16493 16466 16451>,
			<16835 16708 16635 16491 16474 16477>,
			<16853 16714 16668 16506 16499 16509>,
			<16871 16747 16716 16526 16533 16544>,
			<16893 16783 16765 16564 16568 16578>,
			<16965 16826 16807 16597 16558 16558>,
			<17136 16842 16832 16574 16497 16491>,
			<17360 16833 16854 16527 16485 16481>,
			<17756 16913 16918 16542 16493 16481>,
			<19017 17390 17163 16585 16521 16492>,
			<19017 17390 17163 16585 16521 16492>,
			<19017 17390 17163 16585 16521 16492>;
	};

	qcom,pc-temp-y5-lut {
		qcom,lut-col-legend = <(-10) 0 10 25 40 50>;
		qcom,lut-row-legend = <10000 9800 9600 9400 9200 9000>,
			<8800 8600 8400 8200 8000 7800>,
			<7600 7400 7200 7000 6800 6600>,
			<6400 6200 6000 5800 5600 5400>,
			<5200 5000 4800 4600 4400 4200>,
			<4000 3800 3600 3400 3200 3000>,
			<2800 2600 2400 2200 2000 1800>,
			<1600 1400 1200 1000 900 800>,
			<700 600 500 400 300 200>,
			<100 0>;
		qcom,lut-data = <14609 12580 15364 19304 17440 26143>,
			<13378 12482 16152 18868 17445 23448>,
			<12830 12718 16989 18432 17448 21189>,
			<12831 13229 17745 17997 17448 19462>,
			<13242 13957 18289 17562 17446 18364>,
			<13935 14846 18490 17127 17440 17997>,
			<16505 16299 18376 16684 17279 18667>,
			<19662 17722 18147 16249 16980 19627>,
			<19358 17344 17932 15818 16736 19409>,
			<15612 14376 17710 15364 16524 17760>,
			<13437 12569 17377 15182 16234 16828>,
			<16827 14874 16351 15368 15526 17356>,
			<21538 18615 15224 15600 14801 18065>,
			<21058 20339 15432 15490 14892 18112>,
			<15983 21368 17183 15019 15654 17841>,
			<13167 21763 19071 14799 16055 17446>,
			<13339 21432 20901 14845 15574 16543>,
			<13616 20687 22480 14959 14959 15643>,
			<13790 19435 23148 16372 15058 15589>,
			<13932 17064 23554 20526 15912 15839>,
			<13984 15754 23686 23191 17166 16248>,
			<13836 15673 23507 24429 20193 17582>,
			<13570 15618 23140 25101 23129 19053>,
			<13293 15214 22472 23694 22635 19478>,
			<12961 13945 21291 19898 19863 19685>,
			<12825 13224 20793 18519 18193 19723>,
			<12833 13175 21350 18715 17700 18969>,
			<12854 13151 21992 18898 17441 17802>,
			<12960 13193 21921 18548 17559 16776>,
			<13246 13384 21405 17712 18085 15727>,
			<13371 13555 20850 17539 18704 15392>,
			<13156 13656 20295 18661 19532 16019>,
			<12888 13740 19728 20122 20288 17081>,
			<12815 13810 19157 21413 20644 18421>,
			<12786 13865 18584 22618 20884 20164>,
			<12744 13952 18406 22843 20947 21120>,
			<12641 14264 18695 22318 20869 21555>,
			<12553 14592 18996 21654 20771 21780>,
			<12598 14586 18065 21144 20734 21773>,
			<12770 14409 15478 20628 20712 21730>,
			<12909 14271 14678 20008 20647 21750>,
			<12986 14222 17573 19248 20246 22175>,
			<13074 14146 18688 18513 19290 22015>,
			<13191 13819 15438 17794 16638 19146>,
			<14079 13651 14606 16966 16881 19209>,
			<13925 13525 15025 17410 17414 17506>,
			<13895 14133 14804 17424 17670 16731>,
			<14156 13851 14868 17794 17357 16203>,
			<14462 14063 15913 18369 17631 16104>,
			<13747 14066 16610 18381 17847 15664>,
			<12402 14599 16640 19065 18232 17085>,
			<11637 14162 15634 20085 18100 16478>,
			<10762 12879 14369 19483 19529 17317>,
			<9887 11151 12646 20141 23548 22950>,
			<9887 11151 12646 20141 23548 22950>,
			<9887 11151 12646 20141 23548 22950>;
	};

	qcom,pc-temp-y6-lut {
		qcom,lut-col-legend = <(-10) 0 10 25 40 50>;
		qcom,lut-row-legend = <10000 9800 9600 9400 9200 9000>,
			<8800 8600 8400 8200 8000 7800>,
			<7600 7400 7200 7000 6800 6600>,
			<6400 6200 6000 5800 5600 5400>,
			<5200 5000 4800 4600 4400 4200>,
			<4000 3800 3600 3400 3200 3000>,
			<2800 2600 2400 2200 2000 1800>,
			<1600 1400 1200 1000 900 800>,
			<700 600 500 400 300 200>,
			<100 0>;
		qcom,lut-data = <6258 5840 5275 5044 5003 4991>,
			<6241 5837 5279 5042 5003 4990>,
			<6226 5833 5281 5041 5002 4990>,
			<6211 5828 5280 5041 5003 4990>,
			<6198 5823 5279 5040 5003 4989>,
			<6188 5816 5276 5040 5003 4989>,
			<6180 5810 5272 5041 5004 4990>,
			<6173 5802 5267 5041 5005 4991>,
			<6157 5789 5265 5042 5006 4992>,
			<6126 5766 5263 5044 5008 4993>,
			<6109 5753 5263 5045 5010 4994>,
			<6115 5783 5265 5048 5011 4996>,
			<6123 5825 5269 5051 5013 4998>,
			<6105 5812 5276 5056 5016 5000>,
			<6024 5717 5287 5063 5020 5002>,
			<5980 5657 5291 5068 5024 5004>,
			<5980 5654 5271 5071 5027 5006>,
			<5981 5652 5242 5074 5030 5008>,
			<5982 5645 5229 5079 5035 5012>,
			<5985 5627 5222 5088 5043 5019>,
			<5987 5614 5215 5090 5045 5022>,
			<5989 5609 5203 5067 5032 5013>,
			<5991 5606 5191 5040 5013 5000>,
			<5994 5606 5186 5032 5004 4993>,
			<6002 5613 5183 5027 4999 4988>,
			<6012 5622 5182 5026 4997 4986>,
			<6026 5638 5184 5027 4998 4987>,
			<6043 5660 5187 5029 5000 4988>,
			<6059 5682 5190 5030 5002 4989>,
			<6076 5706 5193 5032 5005 4991>,
			<6095 5732 5197 5035 5008 4994>,
			<6118 5760 5202 5038 5012 4998>,
			<6144 5789 5207 5042 5015 5002>,
			<6170 5821 5215 5045 5015 5003>,
			<6196 5855 5226 5048 5016 5005>,
			<6225 5891 5239 5049 5015 5005>,
			<6257 5930 5256 5047 5012 4999>,
			<6291 5971 5274 5046 5008 4994>,
			<6328 6016 5291 5047 5008 4994>,
			<6369 6064 5307 5047 5008 4996>,
			<6415 6108 5328 5048 5009 4998>,
			<6469 6146 5356 5051 5012 5002>,
			<6532 6186 5390 5051 5012 5002>,
			<6612 6234 5432 5049 5006 4992>,
			<6697 6290 5483 5050 5007 4992>,
			<6687 6291 5495 5053 5015 5003>,
			<6774 6350 5542 5062 5024 5015>,
			<6896 6406 5601 5072 5036 5026>,
			<7060 6478 5649 5088 5049 5038>,
			<7374 6554 5701 5099 5046 5030>,
			<7940 6637 5769 5093 5026 5010>,
			<8744 6743 5869 5081 5023 5007>,
			<9964 7125 6055 5096 5031 5012>,
			<12173 8019 6461 5128 5047 5023>,
			<12173 8019 6461 5128 5047 5023>,
			<12173 8019 6461 5128 5047 5023>;
	};

};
